# N32G003 register map
Vendor: Nationstech Ltd.; File version: 1.0
Registers are 32-bit, read-write, reset 0x0 unless marked. A register's access mark holds for its fields unless they carry their own. Offsets are from the block's base; lines under a group give offsets from that group; [hi:lo] are bit positions; {n}, {i} and the like mark numbered series; 'fields as' and 'values as' point back to an identical list; <NAME> marks a mode.

## Memory map
0x40000400 TIM3 size 0x400 — General purpose timer
0x40000C00 TIM1 size 0x400 — Advanced timer
0x40001000 TIM6 size 0x400 — Basic timer
0x40001400 AFIO size 0x400 — Alternate function I/O
0x40001C00 GPIOA size 0x400 — General purpose I/O
0x40002000 GPIOB size 0x400 — General purpose I/O
0x40002400 COMP size 0x400 — comparator
0x40002C00 IWDG size 0x400 — Independent watchdog
0x40003400 EXTI size 0x400 — external interrupt/event controller
0x40003800 BEEPER size 0x400 — Beeper unit
0x40004400 UART1 size 0x400 — Universal asynchronous receiver transmitter
0x40004800 UART2 size 0x400
0x40005400 I2C size 0x400 — Inter integrated circuit
0x40005800 SPI size 0x400 — Serial peripheral interface
0x40007000 PWR size 0x400 — Power control
0x40020800 ADC size 0x400 — analog to digital converter
0x40021000 RCC size 0x400 — Reset and clock control
0x40022000 FLASH size 0x400 — interal FLASH controller
0x40023000 CRC size 0x400 — cyclic redundancy check

## Interrupts
0 PVD (PWR) — PVD through EXTI line18 detection interrupt
1 FLASH — FLASH global interrupt
2 EXTI0_1 (EXTI) — EXTI0/1 interrupt
3 EXTI2_3 (EXTI) — EXTI2/3 interrupt
4 EXTI4_17 (EXTI) — EXTI4/5/6/7/8/9/10/11/12/13/14/15/16/17 interrupt
5 TIM1_BRK_UP_TRG_COM (TIM1) — TIM1 Break/Update/Trigger/Commutation interrupt
6 TIM1_CC (TIM1) — TIM1 Capture Compare interrupt
7 TIM3 — TIM3 global interrupt
8 TIM6 — TIM6 through EXTI line19 detection interrupt
9 ADC — ADC global interrupt
10 I2C_EV (I2C) — I2C event interrupt
11 I2C_ER (I2C) — I2C error interrupt
12 SPI — SPI global interrupt
13 UART1 — UART1 global interrupt
14 UART2 — UART2 global interrupt
15 COMP — COMP global interrupt

## ADC — analog to digital converter
Base 0x40020800
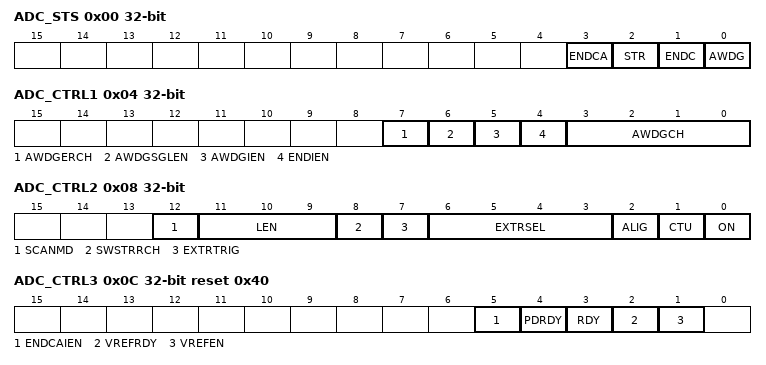
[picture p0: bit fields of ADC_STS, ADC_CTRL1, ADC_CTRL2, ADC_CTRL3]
0x00 ADC_STS
  [3] ENDCA, [2] STR, [1] ENDC, [0] AWDG
0x04 ADC_CTRL1
  [7] AWDGERCH, [6] AWDGSGLEN, [5] AWDGIEN, [4] ENDIEN, [3:0] AWDGCH
0x08 ADC_CTRL2
  [12] SCANMD, [11:9] LEN, [8] SWSTRRCH, [7] EXTRTRIG, [6:3] EXTRSEL, [2] ALIG, [1] CTU, [0] ON
0x0C ADC_CTRL3 reset 0x40
  [5] ENDCAIEN, [4] PDRDY, [3] RDY, [2] VREFRDY, [1] VREFEN
0x10 ADC_SAMPT
  [4:0] SAMP
0x14 ADC_WDGHIGH reset 0xFFF
  [11:0] HTH
0x18 ADC_WDGLOW
  [11:0] LTH
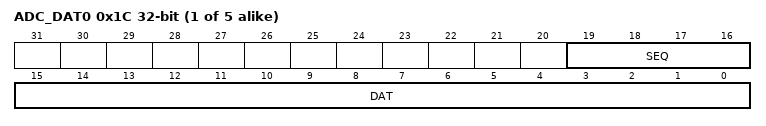
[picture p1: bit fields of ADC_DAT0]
{0x1C+4i} ADC_DAT{i} (i=0..4)
  [19:16] SEQ, [15:0] DAT

## BEEPER — Beeper unit
Base 0x40003800
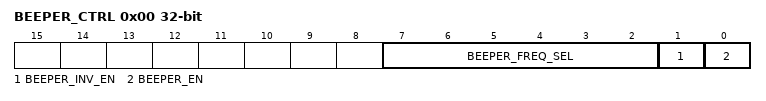
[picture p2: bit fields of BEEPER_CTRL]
0x00 BEEPER_CTRL
  [7:2] BEEPER_FREQ_SEL, [1] BEEPER_INV_EN, [0] BEEPER_EN

## COMP — comparator
Base 0x40002400
0x00 COMP_INTEN
  [0] CMPIEN
0x04 COMP_INTSTS
  [0] CMPIS
0x0C COMP_LOCK
  [0] CMPLK
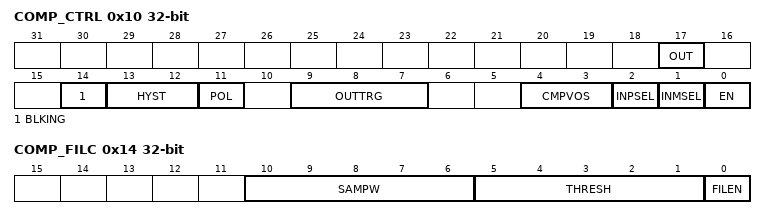
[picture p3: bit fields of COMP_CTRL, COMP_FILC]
0x10 COMP_CTRL
  [17] OUT, [14] BLKING, [13:12] HYST, [11] POL, [9:7] OUTTRG, [4:3] CMPVOS, [2] INPSEL, [1] INMSEL, [0] EN
0x14 COMP_FILC
  [10:6] SAMPW, [5:1] THRESH, [0] FILEN
0x18 COMP_FILP
  [15:0] CLKPSC

## CRC — cyclic redundancy check
Base 0x40023000
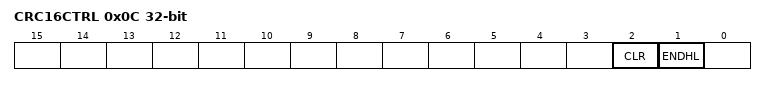
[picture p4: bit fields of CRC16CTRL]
0x0C CRC16CTRL
  [2] CLR, [1] ENDHL
0x10 CRC16DAT
  [7:0] CRC16DAT
0x14 CRC16D
  [15:0] CRC16D
0x18 LRC
  [7:0] LRCDAT

## EXTI — external interrupt/event controller
Base 0x40003400
0x00 EXTI_IMASK
  [19:0] IMASK
0x04 EXTI_EMASK
  [19:0] EMASK
0x08 EXTI_RT_CFG
  [19:0] RT_CFG
0x0C EXTI_FT_CFG
  [19:0] FT_CFG
0x10 EXTI_SWIE
  [19:0] SWIE
0x14 EXTI_PEND
  [19:0] PEND

## FLASH — interal FLASH controller
Base 0x40022000
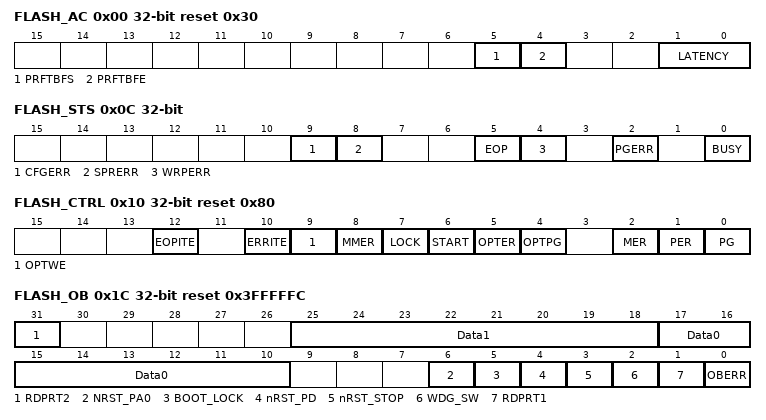
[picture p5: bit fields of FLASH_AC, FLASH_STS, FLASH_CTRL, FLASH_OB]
0x00 FLASH_AC reset 0x30
  [5] PRFTBFS, [4] PRFTBFE, [1:0] LATENCY
0x04 FLASH_KEY
  [31:0] FKEY
0x08 FLASH_OPTKEY
0x0C FLASH_STS
  [9] CFGERR, [8] SPRERR, [5] EOP, [4] WRPERR, [2] PGERR, [0] BUSY
0x10 FLASH_CTRL reset 0x80
  [12] EOPITE, [10] ERRITE, [9] OPTWE, [8] MMER, [7] LOCK, [6] START, [5] OPTER, [4] OPTPG, [2] MER, [1] PER, [0] PG
0x14 FLASH_ADD
  [31:0] FADD
0x1C FLASH_OB reset 0x3FFFFFC
  [31] RDPRT2, [25:18] Data1, [17:10] Data0, [6] NRST_PA0, [5] BOOT_LOCK, [4] nRST_PD, [3] nRST_STOP, [2] WDG_SW, [1] RDPRT1, [0] OBERR
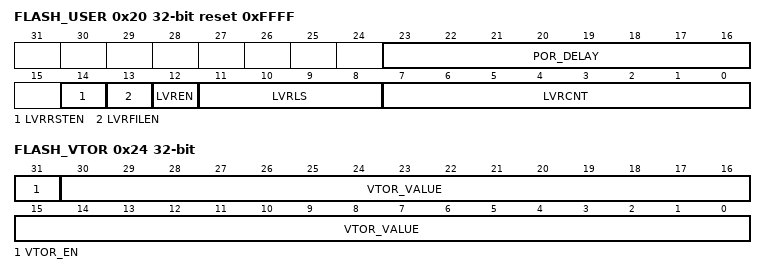
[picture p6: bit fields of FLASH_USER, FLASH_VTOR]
0x20 FLASH_USER reset 0xFFFF (reset mask 0xFF3FFF)
  [23:16] POR_DELAY, [14] LVRRSTEN, [13] LVRFILEN, [12] LVREN, [11:8] LVRLS, [7:0] LVRCNT
0x24 FLASH_VTOR
  [31] VTOR_EN, [30:0] VTOR_VALUE
